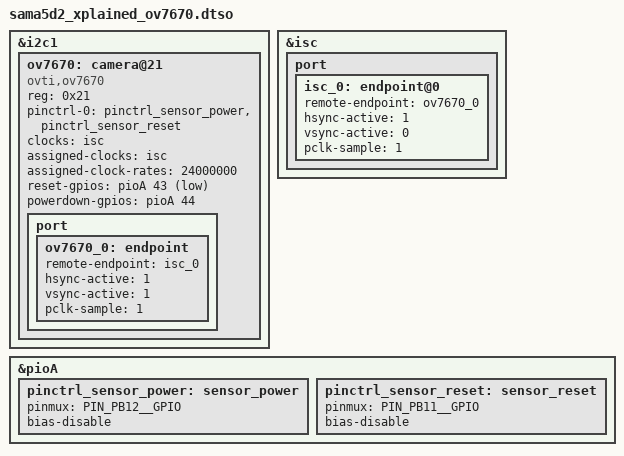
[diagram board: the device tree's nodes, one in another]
// SPDX-License-Identifier: (GPL-2.0+ OR MIT)
/*
 * at91-sama5d2_xplained_ov7670.dtso - Device Tree file for SAMA5D2 Xplained board
 * overlay blob for Image Sensor Controller Omnivision ov7670 sensor.
 *
 * Copyright (C) 2018 Microchip Technology, Inc.
 * Author: Eugen Hristev <eugen.hristev@microchip.com>
 *
 */
/dts-v1/;
/plugin/;

#include "sama5d2-pinfunc.h"
#include <dt-bindings/gpio/gpio.h>

&i2c1 {
	#address-cells = <1>;
	#size-cells = <0>;
	ov7670: camera@21 {
		compatible = "ovti,ov7670";
		reg = <0x21>;
		pinctrl-names = "default";
		pinctrl-0 = <&pinctrl_sensor_power &pinctrl_sensor_reset>;
		clocks = <&isc>;
		clock-names = "xclk";
		assigned-clocks = <&isc>;
		assigned-clock-rates = <24000000>;
		reset-gpios = <&pioA 43 GPIO_ACTIVE_LOW>;
		powerdown-gpios = <&pioA 44 GPIO_ACTIVE_HIGH>;

		port {
			ov7670_0: endpoint {
				remote-endpoint = <&isc_0>;
				hsync-active = <1>;
				vsync-active = <1>;
				pclk-sample = <1>;
			};
		};
	};
};

&isc {
	port {
		isc_0: endpoint@0 {
			remote-endpoint = <&ov7670_0>;
			hsync-active = <1>;
			vsync-active = <0>;
			pclk-sample = <1>;
		};
	};
};

&pioA {
	pinctrl_sensor_power: sensor_power {
		pinmux = <PIN_PB12__GPIO>;
		bias-disable;
	};

	pinctrl_sensor_reset: sensor_reset {
		pinmux = <PIN_PB11__GPIO>;
		bias-disable;
	};
};
